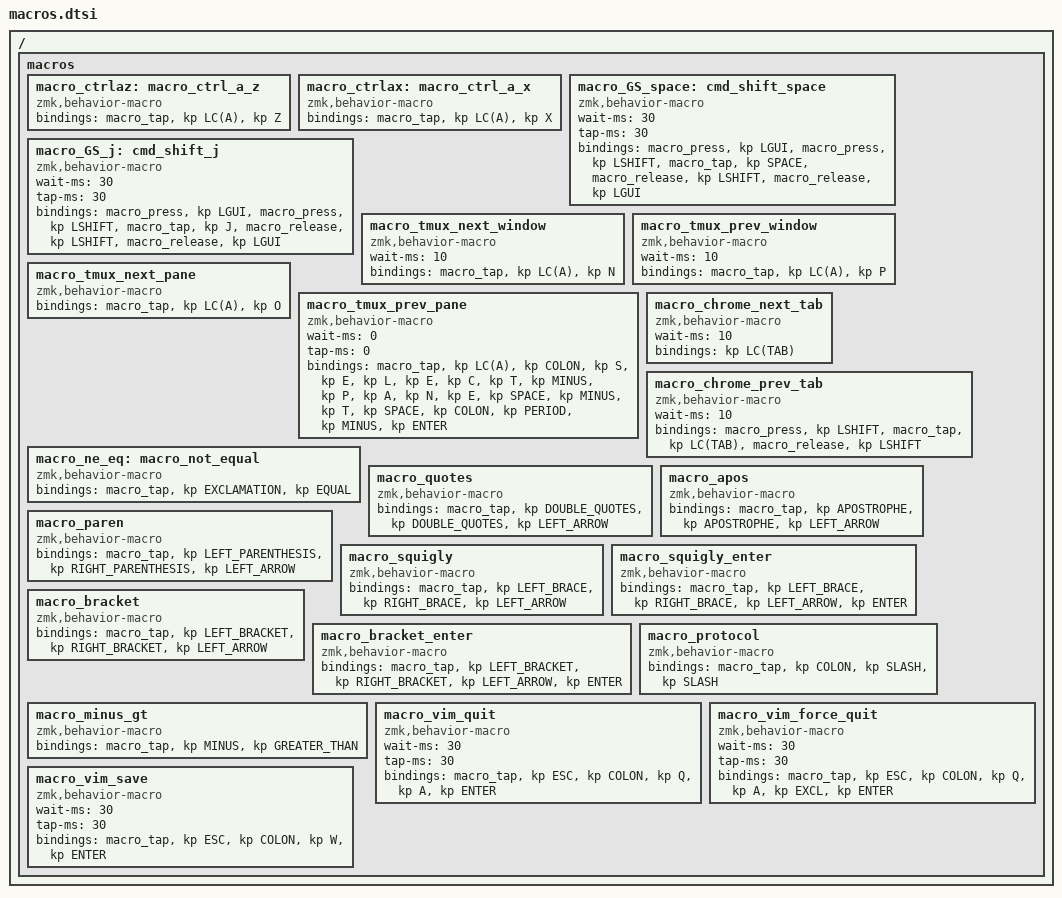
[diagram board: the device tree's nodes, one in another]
/ {
  macros {
    macro_ctrlaz: macro_ctrl_a_z {
      compatible = "zmk,behavior-macro";
      //label = "{} + Return";
      #binding-cells = <0>;
      bindings
      = <&macro_tap &kp LC(A) &kp Z>
      ;
    };
    macro_ctrlax: macro_ctrl_a_x {
      compatible = "zmk,behavior-macro";
      //label = "{} + Return";
      #binding-cells = <0>;
      bindings
      = <&macro_tap &kp LC(A) &kp X>
      ;
    };
    macro_GS_space: cmd_shift_space { // GUI + SHIFT + SPACE
      compatible = "zmk,behavior-macro";
      //label = "Cmd + Shift + Space";
      #binding-cells = <0>;
      wait-ms = <30>;
      tap-ms = <30>;
      bindings
      = <&macro_press &kp LGUI>
      , <&macro_press &kp LSHIFT>
      , <&macro_tap &kp SPACE>
      , <&macro_release &kp LSHIFT>
      , <&macro_release &kp LGUI>
      ;
    };
    macro_GS_j: cmd_shift_j { // GUI + SHIFT + J
      compatible = "zmk,behavior-macro";
      //label = "Cmd + Shift + J";
      #binding-cells = <0>;
      wait-ms = <30>;
      tap-ms = <30>;
      bindings
      = <&macro_press &kp LGUI>
      , <&macro_press &kp LSHIFT>
      , <&macro_tap &kp J>
      , <&macro_release &kp LSHIFT>
      , <&macro_release &kp LGUI>
      ;
    };
    macro_tmux_next_window: macro_tmux_next_window { // Ctrl+A + N
      compatible = "zmk,behavior-macro";
      //label = "Next Tmux Window";
      #binding-cells = <0>;
      wait-ms = <10>;
      bindings
      = <&macro_tap &kp LC(A)>
      , <&kp N>
      ;
    };
    macro_tmux_prev_window: macro_tmux_prev_window { // Ctrl+A + P
      compatible = "zmk,behavior-macro";
      //label = "Previous Tmux Window";
      #binding-cells = <0>;
      wait-ms = <10>;
      bindings
      = <&macro_tap &kp LC(A)>
      , <&kp P>
      ;
    };
    macro_tmux_next_pane: macro_tmux_next_pane { // Ctrl+A + O
      compatible = "zmk,behavior-macro";
      //label = "Tmux Next Pane";
      #binding-cells = <0>;
      bindings
      = <&macro_tap &kp LC(A)>
      , <&kp O>
      ;
    };
    // There is no inverse for <Prefix o> in TMUX, so we do this instead :select-pane -t :.- followed by an ENTER
    macro_tmux_prev_pane: macro_tmux_prev_pane {
      compatible = "zmk,behavior-macro";
      //label = "Tmux Previous Pane";
      wait-ms = <0>;
      tap-ms = <0>;
      #binding-cells = <0>;
      bindings
      = <&macro_tap &kp LC(A)>
      , <&kp COLON>
      , <&kp S &kp E &kp L &kp E &kp C &kp T &kp MINUS &kp P &kp A &kp N &kp E &kp SPACE &kp MINUS &kp T &kp SPACE &kp COLON &kp PERIOD &kp MINUS>
      , <&kp ENTER>
      ;
    };
    macro_chrome_next_tab: macro_chrome_next_tab { // Ctrl + TAB
      compatible = "zmk,behavior-macro";
      //label = "MacOS Chrome Next Tab";
      #binding-cells = <0>;
      wait-ms = <10>;
      bindings = <&kp LC(TAB)>;
    };
    macro_chrome_prev_tab: macro_chrome_prev_tab { // Shift + Ctrl + TAB
      compatible = "zmk,behavior-macro";
      //label = "MacOS Chrome Previous Tab";
      #binding-cells = <0>;
      wait-ms = <10>;
      bindings
      = <&macro_press &kp LSHIFT>
      , <&macro_tap &kp LC(TAB)>
      , <&macro_release &kp LSHIFT>
      ;
    };
    macro_ne_eq: macro_not_equal {
      compatible = "zmk,behavior-macro";
      //label = "!=";
      #binding-cells = <0>;
      bindings
      = <&macro_tap &kp EXCLAMATION &kp EQUAL>
      ;
    };
    macro_quotes: macro_quotes {
      compatible = "zmk,behavior-macro";
      //label = "Quotes and position cursor inside";
      #binding-cells = <0>;
      bindings
      = <&macro_tap &kp DOUBLE_QUOTES &kp DOUBLE_QUOTES &kp LEFT_ARROW>
      ;
    };
    macro_apos: macro_apos {
      compatible = "zmk,behavior-macro";
      //label = "Apos and position cursor inside";
      #binding-cells = <0>;
      bindings
      = <&macro_tap &kp APOSTROPHE &kp APOSTROPHE &kp LEFT_ARROW>
      ;
    };
    macro_paren: macro_paren {
      compatible = "zmk,behavior-macro";
      //label = "()";
      #binding-cells = <0>;
      bindings
      = <&macro_tap &kp LEFT_PARENTHESIS &kp RIGHT_PARENTHESIS &kp LEFT_ARROW>
      ;
    };
    macro_squigly: macro_squigly {
      compatible = "zmk,behavior-macro";
      //label = "{}";
      #binding-cells = <0>;
      bindings
      = <&macro_tap &kp LEFT_BRACE &kp RIGHT_BRACE &kp LEFT_ARROW>
      ;
    };
    macro_squigly_enter: macro_squigly_enter {
      compatible = "zmk,behavior-macro";
      //label = "{} + Return";
      #binding-cells = <0>;
      bindings
      = <&macro_tap &kp LEFT_BRACE &kp RIGHT_BRACE &kp LEFT_ARROW &kp ENTER>
      ;
    };
    macro_bracket: macro_bracket {
      compatible = "zmk,behavior-macro";
      //label = "{}";
      #binding-cells = <0>;
      bindings
      = <&macro_tap &kp LEFT_BRACKET &kp RIGHT_BRACKET &kp LEFT_ARROW>
      ;
    };
    macro_bracket_enter: macro_bracket_enter {
      compatible = "zmk,behavior-macro";
      //label = "{}";
      #binding-cells = <0>;
      bindings
      = <&macro_tap &kp LEFT_BRACKET &kp RIGHT_BRACKET &kp LEFT_ARROW &kp ENTER>
      ;
    };
    macro_protocol: macro_protocol {
      compatible = "zmk,behavior-macro";
      //label = "://";
      #binding-cells = <0>;
      bindings
      = <&macro_tap &kp COLON &kp SLASH &kp SLASH>
      ;
    };
    macro_minus_gt: macro_minus_gt {
      compatible = "zmk,behavior-macro";
      //label = "://";
      #binding-cells = <0>;
      bindings
      = <&macro_tap &kp MINUS &kp GREATER_THAN>
      ;
    };
    macro_vim_quit: macro_vim_quit {
      compatible = "zmk,behavior-macro";
      #binding-cells = <0>;
      wait-ms = <30>;
      tap-ms = <30>;
      bindings = <&macro_tap &kp ESC &kp COLON &kp Q &kp A &kp ENTER>;
    };
    macro_vim_force_quit: macro_vim_force_quit {
      compatible = "zmk,behavior-macro";
      #binding-cells = <0>;
      wait-ms = <30>;
      tap-ms = <30>;
      bindings = <&macro_tap &kp ESC &kp COLON &kp Q &kp A &kp EXCL &kp ENTER>;
    };
    macro_vim_save: macro_vim_save {
      compatible = "zmk,behavior-macro";
      #binding-cells = <0>;
      wait-ms = <30>;
      tap-ms = <30>;
      bindings = <&macro_tap &kp ESC &kp COLON &kp W &kp ENTER>;
    };
  };
};
